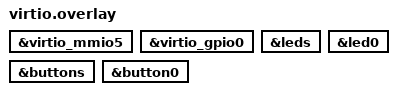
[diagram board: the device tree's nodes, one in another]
/*
 * SPDX-FileCopyrightText: Copyright The Zephyr Project Contributors
 *
 * SPDX-License-Identifier: Apache-2.0
 *
 * Application overlay for testing the VIRTIO GPIO driver build
 */

&virtio_mmio5 {
	status = "okay";
};

&virtio_gpio0 {
	status = "okay";
};

&leds {
	status = "okay";
};

&led0 {
	status = "okay";
};

&buttons {
	status = "okay";
};

&button0 {
	status = "okay";
};
